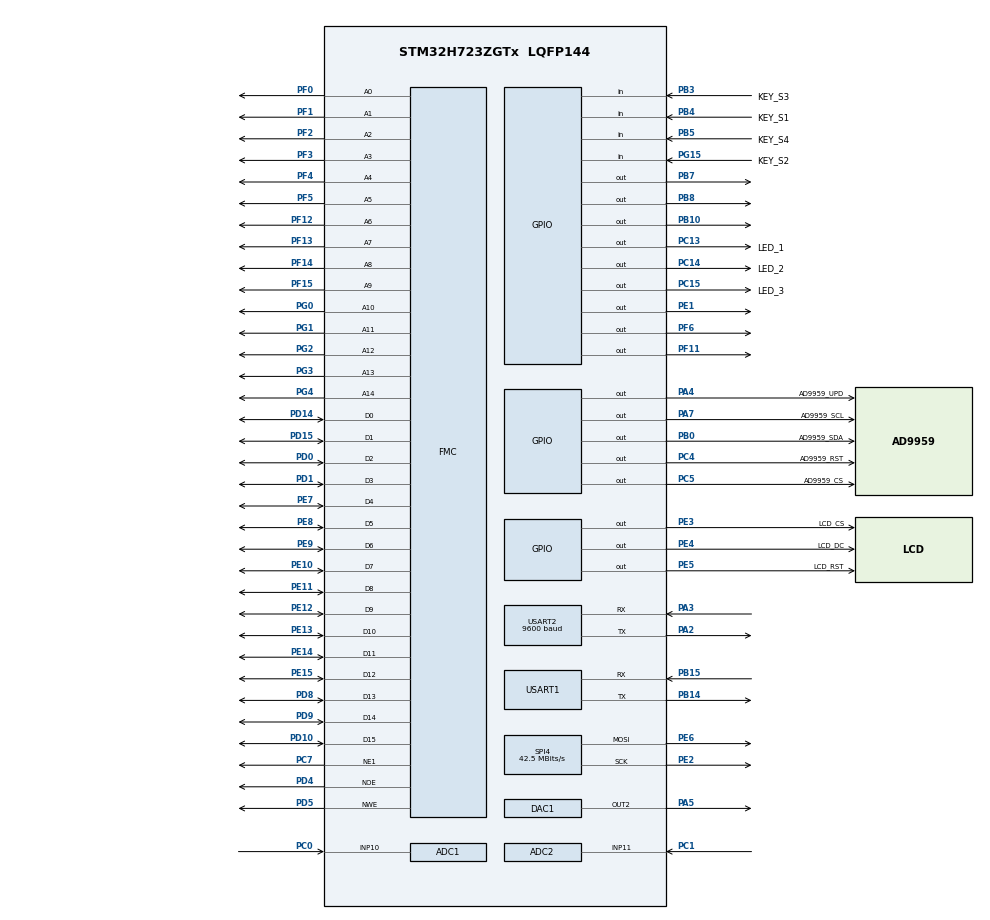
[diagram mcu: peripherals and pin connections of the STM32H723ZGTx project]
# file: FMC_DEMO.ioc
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ADC1.Channel-3\#ChannelRegularConversion=ADC_CHANNEL_10
ADC1.ClockPrescaler=ADC_CLOCK_ASYNC_DIV2
ADC1.ClockPrescalerADC3=ADC_CLOCK_ASYNC_DIV2
ADC1.ConversionDataManagement=ADC_CONVERSIONDATA_DMA_ONESHOT
ADC1.ExternalTrigConv=ADC_EXTERNALTRIG_T6_TRGO
ADC1.Mode=ADC_MODE_INDEPENDENT
ADC1.NbrOfConversionFlag=1
ADC1.OffsetNumber-3\#ChannelRegularConversion=ADC_OFFSET_NONE
ADC1.OffsetSignedSaturation-3\#ChannelRegularConversion=DISABLE
ADC1.Rank-3\#ChannelRegularConversion=1
ADC1.Resolution=ADC_RESOLUTION_12B
ADC1.SamplingTime-3\#ChannelRegularConversion=ADC_SAMPLETIME_1CYCLE_5
ADC1.master=1
ADC2.Channel-3\#ChannelRegularConversion=ADC_CHANNEL_11
ADC2.ClockPrescaler=ADC_CLOCK_ASYNC_DIV2
ADC2.ClockPrescalerADC3=ADC_CLOCK_ASYNC_DIV2
ADC2.ConversionDataManagement=ADC_CONVERSIONDATA_DMA_ONESHOT
ADC2.ExternalTrigConv=ADC_EXTERNALTRIG_T6_TRGO
ADC2.NbrOfConversionFlag=1
ADC2.OffsetNumber-3\#ChannelRegularConversion=ADC_OFFSET_NONE
ADC2.OffsetSignedSaturation-3\#ChannelRegularConversion=DISABLE
ADC2.Rank-3\#ChannelRegularConversion=1
ADC2.Resolution=ADC_RESOLUTION_12B
ADC2.SamplingTime-3\#ChannelRegularConversion=ADC_SAMPLETIME_1CYCLE_5
CORTEX_M7.AccessPermission_Spec=MPU_REGION_FULL_ACCESS
CORTEX_M7.BaseAddress_Spec=0x60000000
CORTEX_M7.CPU_DCache=Enabled
CORTEX_M7.CPU_ICache=Enabled
CORTEX_M7.MPU_Control=MPU_HFNMI_PRIVDEF
CORTEX_M7.Size_Spec=MPU_REGION_SIZE_256MB
CORTEX_M7.SubRegionDisable_Spec=0x00
CORTEX_M7.default_mode_Activation=1
DAC1.DAC_Channel-DAC_OUT2=DAC_CHANNEL_2
Dma.ADC1.0.Direction=DMA_PERIPH_TO_MEMORY
Dma.ADC1.0.EventEnable=DISABLE
Dma.ADC1.0.FIFOMode=DMA_FIFOMODE_DISABLE
Dma.ADC1.0.Instance=DMA1_Stream3
Dma.ADC1.0.MemDataAlignment=DMA_MDATAALIGN_HALFWORD
Dma.ADC1.0.MemInc=DMA_MINC_ENABLE
Dma.ADC1.0.Mode=DMA_NORMAL
Dma.ADC1.0.PeriphDataAlignment=DMA_PDATAALIGN_HALFWORD
Dma.ADC1.0.PeriphInc=DMA_PINC_DISABLE
Dma.ADC1.0.Polarity=HAL_DMAMUX_REQ_GEN_RISING
Dma.ADC1.0.Priority=DMA_PRIORITY_LOW
Dma.ADC1.0.RequestNumber=1
Dma.ADC1.0.SignalID=NONE
Dma.ADC1.0.SyncEnable=DISABLE
Dma.ADC1.0.SyncPolarity=HAL_DMAMUX_SYNC_NO_EVENT
Dma.ADC1.0.SyncRequestNumber=1
Dma.ADC1.0.SyncSignalID=NONE
Dma.ADC2.1.Direction=DMA_PERIPH_TO_MEMORY
Dma.ADC2.1.EventEnable=DISABLE
Dma.ADC2.1.FIFOMode=DMA_FIFOMODE_DISABLE
Dma.ADC2.1.Instance=DMA1_Stream0
Dma.ADC2.1.MemDataAlignment=DMA_MDATAALIGN_HALFWORD
Dma.ADC2.1.MemInc=DMA_MINC_ENABLE
Dma.ADC2.1.Mode=DMA_NORMAL
Dma.ADC2.1.PeriphDataAlignment=DMA_PDATAALIGN_HALFWORD
Dma.ADC2.1.PeriphInc=DMA_PINC_DISABLE
Dma.ADC2.1.Polarity=HAL_DMAMUX_REQ_GEN_RISING
Dma.ADC2.1.Priority=DMA_PRIORITY_LOW
Dma.ADC2.1.RequestNumber=1
Dma.ADC2.1.SignalID=NONE
Dma.ADC2.1.SyncEnable=DISABLE
Dma.ADC2.1.SyncPolarity=HAL_DMAMUX_SYNC_NO_EVENT
Dma.ADC2.1.SyncRequestNumber=1
Dma.ADC2.1.SyncSignalID=NONE
Dma.Request0=ADC1
Dma.Request1=ADC2
Dma.Request2=USART1_RX
Dma.Request3=USART1_TX
Dma.Request4=USART2_RX
Dma.Request5=USART2_TX
Dma.USART1_RX.2.Direction=DMA_PERIPH_TO_MEMORY
Dma.USART1_RX.2.EventEnable=DISABLE
Dma.USART1_RX.2.FIFOMode=DMA_FIFOMODE_DISABLE
Dma.USART1_RX.2.Instance=DMA1_Stream1
Dma.USART1_RX.2.MemDataAlignment=DMA_MDATAALIGN_BYTE
Dma.USART1_RX.2.MemInc=DMA_MINC_ENABLE
Dma.USART1_RX.2.Mode=DMA_NORMAL
Dma.USART1_RX.2.PeriphDataAlignment=DMA_PDATAALIGN_BYTE
Dma.USART1_RX.2.PeriphInc=DMA_PINC_DISABLE
Dma.USART1_RX.2.Polarity=HAL_DMAMUX_REQ_GEN_RISING
Dma.USART1_RX.2.Priority=DMA_PRIORITY_LOW
Dma.USART1_RX.2.RequestNumber=1
Dma.USART1_RX.2.SignalID=NONE
Dma.USART1_RX.2.SyncEnable=DISABLE
Dma.USART1_RX.2.SyncPolarity=HAL_DMAMUX_SYNC_NO_EVENT
Dma.USART1_RX.2.SyncRequestNumber=1
Dma.USART1_RX.2.SyncSignalID=NONE
Dma.USART1_TX.3.Direction=DMA_MEMORY_TO_PERIPH
Dma.USART1_TX.3.EventEnable=DISABLE
Dma.USART1_TX.3.FIFOMode=DMA_FIFOMODE_DISABLE
Dma.USART1_TX.3.Instance=DMA1_Stream2
Dma.USART1_TX.3.MemDataAlignment=DMA_MDATAALIGN_BYTE
Dma.USART1_TX.3.MemInc=DMA_MINC_ENABLE
Dma.USART1_TX.3.Mode=DMA_NORMAL
Dma.USART1_TX.3.PeriphDataAlignment=DMA_PDATAALIGN_BYTE
Dma.USART1_TX.3.PeriphInc=DMA_PINC_DISABLE
Dma.USART1_TX.3.Polarity=HAL_DMAMUX_REQ_GEN_RISING
Dma.USART1_TX.3.Priority=DMA_PRIORITY_LOW
Dma.USART1_TX.3.RequestNumber=1
Dma.USART1_TX.3.SignalID=NONE
Dma.USART1_TX.3.SyncEnable=DISABLE
Dma.USART1_TX.3.SyncPolarity=HAL_DMAMUX_SYNC_NO_EVENT
Dma.USART1_TX.3.SyncRequestNumber=1
Dma.USART1_TX.3.SyncSignalID=NONE
Dma.USART2_RX.4.Direction=DMA_PERIPH_TO_MEMORY
Dma.USART2_RX.4.EventEnable=DISABLE
Dma.USART2_RX.4.FIFOMode=DMA_FIFOMODE_DISABLE
Dma.USART2_RX.4.Instance=DMA1_Stream4
Dma.USART2_RX.4.MemDataAlignment=DMA_MDATAALIGN_BYTE
Dma.USART2_RX.4.MemInc=DMA_MINC_ENABLE
Dma.USART2_RX.4.Mode=DMA_NORMAL
Dma.USART2_RX.4.PeriphDataAlignment=DMA_PDATAALIGN_BYTE
Dma.USART2_RX.4.PeriphInc=DMA_PINC_DISABLE
Dma.USART2_RX.4.Polarity=HAL_DMAMUX_REQ_GEN_RISING
Dma.USART2_RX.4.Priority=DMA_PRIORITY_LOW
Dma.USART2_RX.4.RequestNumber=1
Dma.USART2_RX.4.SignalID=NONE
Dma.USART2_RX.4.SyncEnable=DISABLE
Dma.USART2_RX.4.SyncPolarity=HAL_DMAMUX_SYNC_NO_EVENT
Dma.USART2_RX.4.SyncRequestNumber=1
Dma.USART2_RX.4.SyncSignalID=NONE
Dma.USART2_TX.5.Direction=DMA_MEMORY_TO_PERIPH
Dma.USART2_TX.5.EventEnable=DISABLE
Dma.USART2_TX.5.FIFOMode=DMA_FIFOMODE_DISABLE
Dma.USART2_TX.5.Instance=DMA1_Stream5
Dma.USART2_TX.5.MemDataAlignment=DMA_MDATAALIGN_BYTE
Dma.USART2_TX.5.MemInc=DMA_MINC_ENABLE
Dma.USART2_TX.5.Mode=DMA_NORMAL
Dma.USART2_TX.5.PeriphDataAlignment=DMA_PDATAALIGN_BYTE
Dma.USART2_TX.5.PeriphInc=DMA_PINC_DISABLE
Dma.USART2_TX.5.Polarity=HAL_DMAMUX_REQ_GEN_RISING
Dma.USART2_TX.5.Priority=DMA_PRIORITY_LOW
Dma.USART2_TX.5.RequestNumber=1
Dma.USART2_TX.5.SignalID=NONE
Dma.USART2_TX.5.SyncEnable=DISABLE
Dma.USART2_TX.5.SyncPolarity=HAL_DMAMUX_SYNC_NO_EVENT
Dma.USART2_TX.5.SyncRequestNumber=1
Dma.USART2_TX.5.SyncSignalID=NONE
FMC.AddressHoldTime1=15
FMC.AddressSetupTime1=4
FMC.BusTurnAroundDuration1=2
FMC.DataSetupTime1=3
FMC.WriteFifo1=FMC_WRITE_FIFO_DISABLE
FMC.WriteOperation1=FMC_WRITE_OPERATION_ENABLE
Mcu.Family=STM32H7
Mcu.Name=STM32H723ZGTx
Mcu.Package=LQFP144
Mdma.MDMA_Channel0.Request0=SW
Mdma.MDMA_Channel0.RequestsNb=1
Mdma.MDMA_Channel0.SW.0.BlockCount=0
Mdma.MDMA_Channel0.SW.0.BlockDataLength=0
Mdma.MDMA_Channel0.SW.0.BufferTransferLength=128
Mdma.MDMA_Channel0.SW.0.CircularMode=MDMA_LINEAR_LIST
Mdma.MDMA_Channel0.SW.0.DataAlignment=MDMA_DATAALIGN_PACKENABLE
Mdma.MDMA_Channel0.SW.0.DestBlockAddressOffset=0
Mdma.MDMA_Channel0.SW.0.DestBurst=MDMA_DEST_BURST_8BEATS
Mdma.MDMA_Channel0.SW.0.DestDataSize=MDMA_DEST_DATASIZE_HALFWORD
Mdma.MDMA_Channel0.SW.0.DestinationInc=MDMA_DEST_INC_HALFWORD
Mdma.MDMA_Channel0.SW.0.DstAddress=0
Mdma.MDMA_Channel0.SW.0.Endianness=MDMA_LITTLE_ENDIANNESS_PRESERVE
Mdma.MDMA_Channel0.SW.0.Instance=MDMA_Channel0
Mdma.MDMA_Channel0.SW.0.MaskAddress=0
Mdma.MDMA_Channel0.SW.0.MaskData=0
Mdma.MDMA_Channel0.SW.0.Priority=MDMA_PRIORITY_HIGH
Mdma.MDMA_Channel0.SW.0.Rank=First
Mdma.MDMA_Channel0.SW.0.SourceBlockAddressOffset=0
Mdma.MDMA_Channel0.SW.0.SourceBurst=MDMA_SOURCE_BURST_8BEATS
Mdma.MDMA_Channel0.SW.0.SourceDataSize=MDMA_SRC_DATASIZE_HALFWORD
Mdma.MDMA_Channel0.SW.0.SourceInc=MDMA_SRC_INC_HALFWORD
Mdma.MDMA_Channel0.SW.0.SrcAddress=0
Mdma.MDMA_Channel0.SW.0.TransferTriggerMode=MDMA_BUFFER_TRANSFER
Mdma.RequestSet0=MDMA_Channel0
Mdma.RequestSetsNb=1
NVIC.ADC_IRQn=true\:0\:0\:false\:false\:true\:true\:true\:true
NVIC.DMA1_Stream0_IRQn=true\:0\:0\:false\:false\:true\:false\:true\:true
NVIC.DMA1_Stream1_IRQn=true\:0\:0\:false\:false\:true\:false\:true\:true
NVIC.DMA1_Stream2_IRQn=true\:0\:0\:false\:false\:true\:false\:true\:true
NVIC.DMA1_Stream3_IRQn=true\:0\:0\:false\:false\:true\:false\:true\:true
NVIC.DMA1_Stream4_IRQn=true\:0\:0\:false\:false\:true\:false\:true\:true
NVIC.DMA1_Stream5_IRQn=true\:0\:0\:false\:false\:true\:false\:true\:true
NVIC.MDMA_IRQn=true\:0\:0\:false\:false\:true\:false\:true\:true
NVIC.PriorityGroup=NVIC_PRIORITYGROUP_4
NVIC.TIM17_IRQn=true\:0\:0\:false\:false\:true\:true\:true\:true
NVIC.USART1_IRQn=true\:0\:0\:false\:false\:true\:true\:true\:true
NVIC.USART2_IRQn=true\:0\:0\:false\:false\:true\:true\:true\:true
PA2.Mode=Asynchronous
PA2.Signal=USART2_TX
PA3.Mode=Asynchronous
PA3.Signal=USART2_RX
PA4.GPIO_Label=AD9959_UPD
PA4.Signal=GPIO_Output
PA5.Signal=COMP_DAC12_group
PA7.GPIO_Label=AD9959_SCL
PA7.GPIO_Speed=GPIO_SPEED_FREQ_HIGH
PA7.Signal=GPIO_Output
PB0.GPIO_Label=AD9959_SDA
PB0.GPIO_Speed=GPIO_SPEED_FREQ_HIGH
PB0.Signal=GPIO_Output
PB10.Signal=GPIO_Output
PB14.Mode=Asynchronous
PB14.Signal=USART1_TX
PB15.Mode=Asynchronous
PB15.Signal=USART1_RX
PB3(JTDO/TRACESWO).GPIO_Label=KEY_S3
PB3(JTDO/TRACESWO).Signal=GPIO_Input
PB4(NJTRST).GPIO_Label=KEY_S1
PB4(NJTRST).Signal=GPIO_Input
PB5.GPIO_Label=KEY_S4
PB5.Signal=GPIO_Input
PB7.Signal=GPIO_Output
PB8.Signal=GPIO_Output
PC0.Signal=ADCx_INP10
PC1.Signal=ADCx_INP11
PC13.GPIO_Label=LED_1
PC13.PinState=GPIO_PIN_SET
PC13.Signal=GPIO_Output
PC14-OSC32_IN.GPIO_Label=LED_2
PC14-OSC32_IN.PinState=GPIO_PIN_SET
PC14-OSC32_IN.Signal=GPIO_Output
PC15-OSC32_OUT.GPIO_Label=LED_3
PC15-OSC32_OUT.PinState=GPIO_PIN_SET
PC15-OSC32_OUT.Signal=GPIO_Output
PC4.GPIO_Label=AD9959_RST
PC4.Signal=GPIO_Output
PC5.GPIO_Label=AD9959_CS
PC5.Signal=GPIO_Output
PC7.Mode=NorPsramChipSelect1_1
PC7.Signal=FMC_NE1
PD0.Signal=FMC_D2_DA2
PD1.Signal=FMC_D3_DA3
PD10.Signal=FMC_D15_DA15
PD14.Signal=FMC_D0_DA0
PD15.Signal=FMC_D1_DA1
PD4.Signal=FMC_NOE
PD5.Signal=FMC_NWE
PD8.Signal=FMC_D13_DA13
PD9.Signal=FMC_D14_DA14
PE1.Signal=GPIO_Output
PE10.Signal=FMC_D7_DA7
PE11.Signal=FMC_D8_DA8
PE12.Signal=FMC_D9_DA9
PE13.Signal=FMC_D10_DA10
PE14.Signal=FMC_D11_DA11
PE15.Signal=FMC_D12_DA12
PE2.GPIO_Speed=GPIO_SPEED_FREQ_VERY_HIGH
PE2.Mode=TX_Only_Simplex_Unidirect_Master
PE2.Signal=SPI4_SCK
PE3.GPIO_Label=LCD_CS
PE3.GPIO_Speed=GPIO_SPEED_FREQ_LOW
PE3.PinState=GPIO_PIN_SET
PE3.Signal=GPIO_Output
PE4.GPIO_Label=LCD_DC
PE4.PinState=GPIO_PIN_SET
PE4.Signal=GPIO_Output
PE5.GPIO_Label=LCD_RST
PE5.Signal=GPIO_Output
PE6.GPIO_Speed=GPIO_SPEED_FREQ_VERY_HIGH
PE6.Mode=TX_Only_Simplex_Unidirect_Master
PE6.Signal=SPI4_MOSI
PE7.Signal=FMC_D4_DA4
PE8.Signal=FMC_D5_DA5
PE9.Signal=FMC_D6_DA6
PF0.Signal=FMC_A0
PF1.Signal=FMC_A1
PF11.Signal=GPIO_Output
PF12.Signal=FMC_A6
PF13.Signal=FMC_A7
PF14.Signal=FMC_A8
PF15.Signal=FMC_A9
PF2.Signal=FMC_A2
PF3.Signal=FMC_A3
PF4.Signal=FMC_A4
PF5.Signal=FMC_A5
PF6.Signal=GPIO_Output
PG0.Signal=FMC_A10
PG1.Signal=FMC_A11
PG15.GPIO_Label=KEY_S2
PG15.Signal=GPIO_Input
PG2.Signal=FMC_A12
PG3.Signal=FMC_A13
PG4.Signal=FMC_A14_BA0
ProjectManager.HeapSize=0x200
ProjectManager.StackSize=0x400
ProjectManager.TargetToolchain=MDK-ARM V5.32
RCC.ADCCLockSelection=RCC_ADCCLKSOURCE_PLL2
RCC.ADCFreq_Value=100000000
RCC.APB1Freq_Value=137500000
RCC.APB2Freq_Value=137500000
RCC.APB3Freq_Value=137500000
RCC.APB4Freq_Value=137500000
RCC.CECCLockSelection=RCC_CECCLKSOURCE_LSI
RCC.CKPERSourceSelection=RCC_CLKPSOURCE_HSI
RCC.CSI_VALUE=4000000
RCC.CortexFreq_Value=68750000
RCC.Cortex_Div=SYSTICK_CLKSOURCE_HCLK_DIV8
RCC.Cortex_DivARG=SystemCoreClock/1000
RCC.D1CPRE=RCC_SYSCLK_DIV1
RCC.D1PPRE=RCC_APB3_DIV2
RCC.D2PPRE1=RCC_APB1_DIV2
RCC.D2PPRE2=RCC_APB2_DIV2
RCC.D3PPRE=RCC_APB4_DIV2
RCC.DFSDMCLockSelection=RCC_DFSDM1CLKSOURCE_D2PCLK1
RCC.DIVM1=32
RCC.DIVM2=4
RCC.DIVM3=32
RCC.DIVN1=275
RCC.DIVN2=25
RCC.DIVN3=170
RCC.DIVP1=1
RCC.DIVP2=4
RCC.DIVP3=2
RCC.DIVQ1=5
RCC.DIVQ2=4
RCC.DIVQ3=2
RCC.DIVR1=2
RCC.DIVR2=4
RCC.DIVR3=2
RCC.EXTERNAL_CLOCK_VALUE=12288000
RCC.FDCANCLockSelection=RCC_FDCANCLKSOURCE_PLL
RCC.FLatency-AdvancedSettings=FLASH_LATENCY_3
RCC.FMCCLockSelection=RCC_FMCCLKSOURCE_PLL
RCC.HCLKFreq_Value=275000000
RCC.HPRE=RCC_HCLK_DIV2
RCC.HSE_VALUE=25000000
RCC.HSI48_VALUE=48000000
RCC.HSIDiv=RCC_PLLSAIDIVR_1
RCC.HSI_VALUE=64000000
RCC.I2C123CLockSelection=RCC_I2C1235CLKSOURCE_D2PCLK1
RCC.I2C4CLockSelection=RCC_I2C4CLKSOURCE_D3PCLK1
RCC.LPTIM1CLockSelection=RCC_LPTIM1CLKSOURCE_D2PCLK1
RCC.LPTIM2CLockSelection=RCC_LPTIM2CLKSOURCE_D3PCLK1
RCC.LPTIM345CLockSelection=RCC_LPTIM345CLKSOURCE_D3PCLK1
RCC.LPUART1CLockSelection=RCC_LPUART1CLKSOURCE_D3PCLK1
RCC.LSEState=RCC_LSE_OFF
RCC.LSE_VALUE=32768
RCC.PLL3_VCI_Range-AdvancedSettings=RCC_PLL3VCIRANGE_3
RCC.PLLFRACN=0
RCC.QSPICLockSelection=RCC_OSPICLKSOURCE_D1HCLK
RCC.RCC_MCO1Source=RCC_MCO1SOURCE_HSI
RCC.RCC_MCO2Source=RCC_MCO2SOURCE_SYSCLK
RCC.RCC_MCODiv1=RCC_MCODIV_1
RCC.RCC_MCODiv2=RCC_MCODIV_1
RCC.RCC_RTC_Clock_Source_FROM_HSE=RCC_RTCCLKSOURCE_HSE_DIV2
RCC.RNGCLockSelection=RCC_RNGCLKSOURCE_HSI48
RCC.SAI1CLockSelection=RCC_SAI1CLKSOURCE_PLL
RCC.SAI4ACLockSelection=RCC_SAI4ACLKSOURCE_PLL
RCC.SAI4BCLockSelection=RCC_SAI4BCLKSOURCE_PLL
RCC.SPDIFCLockSelection=RCC_SPDIFRXCLKSOURCE_PLL
RCC.SPI123CLockSelection=RCC_SPI123CLKSOURCE_PLL
RCC.SPI6CLockSelection=RCC_SPI6CLKSOURCE_D3PCLK1
RCC.SWPCLockSelection=RCC_SWPMI1CLKSOURCE_D2PCLK1
RCC.SYSCLKFreq_VALUE=550000000
RCC.SYSCLKSource=RCC_SYSCLKSOURCE_PLLCLK
RCC.Spi45ClockSelection=RCC_SPI45CLKSOURCE_PLL3
RCC.USART16CLockSelection=RCC_USART16910CLKSOURCE_D2PCLK2
RCC.USART234578CLockSelection=RCC_USART234578CLKSOURCE_D2PCLK1
RCC.USBCLockSelection=RCC_USBCLKSOURCE_PLL
RCC.USBFreq_Value=110000000
SH.ADCx_INP10.0=ADC1_INP10,IN10-Single-Ended
SH.ADCx_INP11.0=ADC2_INP11,IN11-Single-Ended
SH.COMP_DAC12_group.0=DAC1_OUT2,DAC_OUT2
SH.FMC_A0.0=FMC_A0,15b-a1
SH.FMC_A1.0=FMC_A1,15b-a1
SH.FMC_A10.0=FMC_A10,15b-a1
SH.FMC_A11.0=FMC_A11,15b-a1
SH.FMC_A12.0=FMC_A12,15b-a1
SH.FMC_A13.0=FMC_A13,15b-a1
SH.FMC_A14_BA0.0=FMC_A14,15b-a1
SH.FMC_A2.0=FMC_A2,15b-a1
SH.FMC_A3.0=FMC_A3,15b-a1
SH.FMC_A4.0=FMC_A4,15b-a1
SH.FMC_A5.0=FMC_A5,15b-a1
SH.FMC_A6.0=FMC_A6,15b-a1
SH.FMC_A7.0=FMC_A7,15b-a1
SH.FMC_A8.0=FMC_A8,15b-a1
SH.FMC_A9.0=FMC_A9,15b-a1
SH.FMC_D0_DA0.0=FMC_D0,16b-d1
SH.FMC_D10_DA10.0=FMC_D10,16b-d1
SH.FMC_D11_DA11.0=FMC_D11,16b-d1
SH.FMC_D12_DA12.0=FMC_D12,16b-d1
SH.FMC_D13_DA13.0=FMC_D13,16b-d1
SH.FMC_D14_DA14.0=FMC_D14,16b-d1
SH.FMC_D15_DA15.0=FMC_D15,16b-d1
SH.FMC_D1_DA1.0=FMC_D1,16b-d1
SH.FMC_D2_DA2.0=FMC_D2,16b-d1
SH.FMC_D3_DA3.0=FMC_D3,16b-d1
SH.FMC_D4_DA4.0=FMC_D4,16b-d1
SH.FMC_D5_DA5.0=FMC_D5,16b-d1
SH.FMC_D6_DA6.0=FMC_D6,16b-d1
SH.FMC_D7_DA7.0=FMC_D7,16b-d1
SH.FMC_D8_DA8.0=FMC_D8,16b-d1
SH.FMC_D9_DA9.0=FMC_D9,16b-d1
SH.FMC_NOE.0=FMC_NOE,Sram1
SH.FMC_NWE.0=FMC_NWE,Sram1
SPI4.BaudRatePrescaler=SPI_BAUDRATEPRESCALER_4
SPI4.CalculateBaudRate=42.5 MBits/s
SPI4.DataSize=SPI_DATASIZE_8BIT
SPI4.Direction=SPI_DIRECTION_2LINES_TXONLY
SPI4.Mode=SPI_MODE_MASTER
SPI4.VirtualType=VM_MASTER
TIM17.AutoReloadPreload=TIM_AUTORELOAD_PRELOAD_ENABLE
TIM17.Period=9999
TIM17.Prescaler=274
TIM6.Period=99
TIM6.Prescaler=274
TIM6.TIM_MasterOutputTrigger=TIM_TRGO_UPDATE
USART1.VirtualMode-Asynchronous=VM_ASYNC
USART2.BaudRate=9600
USART2.VirtualMode-Asynchronous=VM_ASYNC
VP_MEMORYMAP_VS_MEMORYMAP.Mode=CurAppReg
VP_TIM17_VS_ClockSourceINT.Mode=Enable_Timer
VP_TIM6_VS_ClockSourceINT.Mode=Enable_Timer
board=custom

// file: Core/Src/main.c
/* USER CODE BEGIN Header */
/**
  ******************************************************************************
  * @file           : main.c
  * @brief          : Main program body
  ******************************************************************************
  * @attention
  *
  * Copyright (c) 2026 STMicroelectronics.
  * All rights reserved.
  *
  * This software is licensed under terms that can be found in the LICENSE file
  * in the root directory of this software component.
  * If no LICENSE file comes with this software, it is provided AS-IS.
  *
  ******************************************************************************
  */
/* USER CODE END Header */
#include "main.h"
#include "adc.h"
#include "dac.h"
#include "dma.h"
#include "mdma.h"
#include "spi.h"
#include "tim.h"
#include "usart.h"
#include "gpio.h"
#include "fmc.h"

/* USER CODE BEGIN Includes */
#include "bsp.h"
/* USER CODE END Includes */

/* USER CODE BEGIN PD */

#define FPGA_BASE_ADDR  0x60000000
#define FPGA           ((volatile uint16_t *)FPGA_BASE_ADDR)

/* USER CODE END PD */

void SystemClock_Config(void);
void PeriphCommonClock_Config(void);
static void MPU_Config(void);

int main(void)
{

  /* MPU Configuration--------------------------------------------------------*/
  MPU_Config();

  /* Enable the CPU Cache */

  /* Enable I-Cache---------------------------------------------------------*/
  SCB_EnableICache();

  /* Enable D-Cache---------------------------------------------------------*/
  SCB_EnableDCache();

  /* MCU Configuration--------------------------------------------------------*/

  /* Reset of all peripherals, Initializes the Flash interface and the Systick. */
  HAL_Init();

  /* Configure the system clock */
  SystemClock_Config();

  /* Configure the peripherals common clocks */
  PeriphCommonClock_Config();

  /* Initialize all configured peripherals */
  MX_GPIO_Init();
  MX_DMA_Init();
  MX_MDMA_Init();
  MX_FMC_Init();
  MX_SPI4_Init();
  MX_USART1_UART_Init();
  MX_USART2_UART_Init();
  MX_ADC1_Init();
  MX_ADC2_Init();
  MX_TIM6_Init();
  MX_DAC1_Init();
  MX_TIM17_Init();
  /* USER CODE BEGIN 2 */

	MainProcess();
  /* USER CODE END 2 */

  /* Infinite loop */
  while (1)
  {

  }
}

void SystemClock_Config(void)
{
  RCC_OscInitTypeDef RCC_OscInitStruct = {0};
  RCC_ClkInitTypeDef RCC_ClkInitStruct = {0};

  /** Supply configuration update enable
  */
  HAL_PWREx_ConfigSupply(PWR_LDO_SUPPLY);

  /** Configure the main internal regulator output voltage
  */
  __HAL_PWR_VOLTAGESCALING_CONFIG(PWR_REGULATOR_VOLTAGE_SCALE0);

  while(!__HAL_PWR_GET_FLAG(PWR_FLAG_VOSRDY)) {}

  /** Initializes the RCC Oscillators according to the specified parameters
  * in the RCC_OscInitTypeDef structure.
  */
  RCC_OscInitStruct.OscillatorType = RCC_OSCILLATORTYPE_HSI;
  RCC_OscInitStruct.HSIState = RCC_HSI_DIV1;
  RCC_OscInitStruct.HSICalibrationValue = 64;
  RCC_OscInitStruct.PLL.PLLState = RCC_PLL_ON;
  RCC_OscInitStruct.PLL.PLLSource = RCC_PLLSOURCE_HSI;
  RCC_OscInitStruct.PLL.PLLM = 32;
  RCC_OscInitStruct.PLL.PLLN = 275;
  RCC_OscInitStruct.PLL.PLLP = 1;
  RCC_OscInitStruct.PLL.PLLQ = 5;
  RCC_OscInitStruct.PLL.PLLR = 2;
  RCC_OscInitStruct.PLL.PLLRGE = RCC_PLL1VCIRANGE_1;
  RCC_OscInitStruct.PLL.PLLVCOSEL = RCC_PLL1VCOWIDE;
  RCC_OscInitStruct.PLL.PLLFRACN = 0;
  if (HAL_RCC_OscConfig(&RCC_OscInitStruct) != HAL_OK)
  {
    Error_Handler();
  }

  /** Initializes the CPU, AHB and APB buses clocks
  */
  RCC_ClkInitStruct.ClockType = RCC_CLOCKTYPE_HCLK|RCC_CLOCKTYPE_SYSCLK
                              |RCC_CLOCKTYPE_PCLK1|RCC_CLOCKTYPE_PCLK2
                              |RCC_CLOCKTYPE_D3PCLK1|RCC_CLOCKTYPE_D1PCLK1;
  RCC_ClkInitStruct.SYSCLKSource = RCC_SYSCLKSOURCE_PLLCLK;
  RCC_ClkInitStruct.SYSCLKDivider = RCC_SYSCLK_DIV1;
  RCC_ClkInitStruct.AHBCLKDivider = RCC_HCLK_DIV2;
  RCC_ClkInitStruct.APB3CLKDivider = RCC_APB3_DIV2;
  RCC_ClkInitStruct.APB1CLKDivider = RCC_APB1_DIV2;
  RCC_ClkInitStruct.APB2CLKDivider = RCC_APB2_DIV2;
  RCC_ClkInitStruct.APB4CLKDivider = RCC_APB4_DIV2;

  if (HAL_RCC_ClockConfig(&RCC_ClkInitStruct, FLASH_LATENCY_3) != HAL_OK)
  {
    Error_Handler();
  }
}

void PeriphCommonClock_Config(void)
{
  RCC_PeriphCLKInitTypeDef PeriphClkInitStruct = {0};

  /** Initializes the peripherals clock
  */
  PeriphClkInitStruct.PeriphClockSelection = RCC_PERIPHCLK_ADC;
  PeriphClkInitStruct.PLL2.PLL2M = 4;
  PeriphClkInitStruct.PLL2.PLL2N = 25;
  PeriphClkInitStruct.PLL2.PLL2P = 4;
  PeriphClkInitStruct.PLL2.PLL2Q = 4;
  PeriphClkInitStruct.PLL2.PLL2R = 4;
  PeriphClkInitStruct.PLL2.PLL2RGE = RCC_PLL2VCIRANGE_3;
  PeriphClkInitStruct.PLL2.PLL2VCOSEL = RCC_PLL2VCOWIDE;
  PeriphClkInitStruct.PLL2.PLL2FRACN = 0;
  PeriphClkInitStruct.AdcClockSelection = RCC_ADCCLKSOURCE_PLL2;
  if (HAL_RCCEx_PeriphCLKConfig(&PeriphClkInitStruct) != HAL_OK)
  {
    Error_Handler();
  }
}

 /* MPU Configuration */

void MPU_Config(void)
{
  MPU_Region_InitTypeDef MPU_InitStruct = {0};

  /* Disables the MPU */
  HAL_MPU_Disable();

  /** Initializes and configures the Region and the memory to be protected
  */
  MPU_InitStruct.Enable = MPU_REGION_ENABLE;
  MPU_InitStruct.Number = MPU_REGION_NUMBER0;
  MPU_InitStruct.BaseAddress = 0x60000000;
  MPU_InitStruct.Size = MPU_REGION_SIZE_256MB;
  MPU_InitStruct.SubRegionDisable = 0x00;
  MPU_InitStruct.TypeExtField = MPU_TEX_LEVEL0;
  MPU_InitStruct.AccessPermission = MPU_REGION_FULL_ACCESS;
  MPU_InitStruct.DisableExec = MPU_INSTRUCTION_ACCESS_DISABLE;
  MPU_InitStruct.IsShareable = MPU_ACCESS_SHAREABLE;
  MPU_InitStruct.IsCacheable = MPU_ACCESS_NOT_CACHEABLE;
  MPU_InitStruct.IsBufferable = MPU_ACCESS_NOT_BUFFERABLE;

  HAL_MPU_ConfigRegion(&MPU_InitStruct);
  /* Enables the MPU */
  HAL_MPU_Enable(MPU_HFNMI_PRIVDEF);

}

void Error_Handler(void)
{
  __disable_irq();
  while (1)
  {
  }
}
